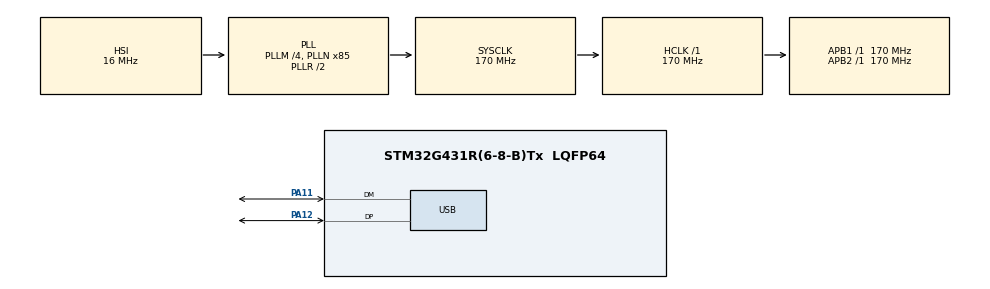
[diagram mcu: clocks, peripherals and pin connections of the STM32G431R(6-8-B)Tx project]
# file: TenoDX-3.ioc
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Mcu.Family=STM32G4
Mcu.Name=STM32G431R(6-8-B)Tx
Mcu.Package=LQFP64
NVIC.PriorityGroup=NVIC_PRIORITYGROUP_4
NVIC.USB_LP_IRQn=true\:0\:0\:false\:false\:true\:true\:true\:true
PA11.Mode=Device
PA11.Signal=USB_DM
PA12.Mode=Device
PA12.Signal=USB_DP
PA13.Mode=Serial_Wire
PA13.Signal=SYS_JTMS-SWDIO
PA14.Mode=Serial_Wire
PA14.Signal=SYS_JTCK-SWCLK
PF0-OSC_IN.Mode=HSE-External-Oscillator
PF0-OSC_IN.Signal=RCC_OSC_IN
PF1-OSC_OUT.Mode=HSE-External-Oscillator
PF1-OSC_OUT.Signal=RCC_OSC_OUT
ProjectManager.HeapSize=0x200
ProjectManager.StackSize=0x400
ProjectManager.TargetToolchain=STM32CubeIDE
RCC.ADC12Freq_Value=170000000
RCC.AHBFreq_Value=170000000
RCC.APB1Freq_Value=170000000
RCC.APB1TimFreq_Value=170000000
RCC.APB2Freq_Value=170000000
RCC.APB2TimFreq_Value=170000000
RCC.CK48CLockSelection=RCC_USBCLKSOURCE_HSI48
RCC.CortexFreq_Value=170000000
RCC.EXTERNAL_CLOCK_VALUE=12288000
RCC.HCLKFreq_Value=170000000
RCC.HSE_VALUE=8000000
RCC.HSI48_VALUE=48000000
RCC.HSI_VALUE=16000000
RCC.LSE_VALUE=32768
RCC.PLLM=RCC_PLLM_DIV4
RCC.PLLN=85
RCC.PLLQ=RCC_PLLQ_DIV4
RCC.SYSCLKFreq_VALUE=170000000
RCC.SYSCLKSource=RCC_SYSCLKSOURCE_PLLCLK
RCC.USBFreq_Value=48000000
RCC.VCOOutputFreq_Value=340000000
VP_SYS_VS_DBSignals.Mode=DisableDeadBatterySignals
board=custom

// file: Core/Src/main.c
/* USER CODE BEGIN Header */
/**
  ******************************************************************************
  * @file           : main.c
  * @brief          : Main program body
  ******************************************************************************
  * @attention
  *
  * Copyright (c) 2026 STMicroelectronics.
  * All rights reserved.
  *
  * This software is licensed under terms that can be found in the LICENSE file
  * in the root directory of this software component.
  * If no LICENSE file comes with this software, it is provided AS-IS.
  *
  ******************************************************************************
  */
/* USER CODE END Header */
#include "main.h"
#include "usb.h"
#include "gpio.h"

/* USER CODE BEGIN Includes */
#include "tusb.h" // 必须包含头文件
/* USER CODE END Includes */

void SystemClock_Config(void);

int main(void)
{

  /* MCU Configuration--------------------------------------------------------*/

  /* Reset of all peripherals, Initializes the Flash interface and the Systick. */
  HAL_Init();

  /* Configure the system clock */
  SystemClock_Config();

  /* Initialize all configured peripherals */
  MX_GPIO_Init();
  MX_USB_PCD_Init();
  /* USER CODE BEGIN 2 */
  PWR->CR2 |= PWR_CR2_USV;
  tusb_init();
  /* USER CODE END 2 */

  /* Infinite loop */
  /* USER CODE BEGIN WHILE */
  while (1)
  {
	  tud_task();
    /* USER CODE END WHILE */

  }
}

void SystemClock_Config(void)
{
  RCC_OscInitTypeDef RCC_OscInitStruct = {0};
  RCC_ClkInitTypeDef RCC_ClkInitStruct = {0};

  /** Configure the main internal regulator output voltage
  */
  HAL_PWREx_ControlVoltageScaling(PWR_REGULATOR_VOLTAGE_SCALE1_BOOST);

  /** Initializes the RCC Oscillators according to the specified parameters
  * in the RCC_OscInitTypeDef structure.
  */
  RCC_OscInitStruct.OscillatorType = RCC_OSCILLATORTYPE_HSI|RCC_OSCILLATORTYPE_HSI48;
  RCC_OscInitStruct.HSIState = RCC_HSI_ON;
  RCC_OscInitStruct.HSICalibrationValue = RCC_HSICALIBRATION_DEFAULT;
  RCC_OscInitStruct.HSI48State = RCC_HSI48_ON;
  RCC_OscInitStruct.PLL.PLLState = RCC_PLL_ON;
  RCC_OscInitStruct.PLL.PLLSource = RCC_PLLSOURCE_HSI;
  RCC_OscInitStruct.PLL.PLLM = RCC_PLLM_DIV4;
  RCC_OscInitStruct.PLL.PLLN = 85;
  RCC_OscInitStruct.PLL.PLLP = RCC_PLLP_DIV2;
  RCC_OscInitStruct.PLL.PLLQ = RCC_PLLQ_DIV4;
  RCC_OscInitStruct.PLL.PLLR = RCC_PLLR_DIV2;
  if (HAL_RCC_OscConfig(&RCC_OscInitStruct) != HAL_OK)
  {
    Error_Handler();
  }

  /** Initializes the CPU, AHB and APB buses clocks
  */
  RCC_ClkInitStruct.ClockType = RCC_CLOCKTYPE_HCLK|RCC_CLOCKTYPE_SYSCLK
                              |RCC_CLOCKTYPE_PCLK1|RCC_CLOCKTYPE_PCLK2;
  RCC_ClkInitStruct.SYSCLKSource = RCC_SYSCLKSOURCE_PLLCLK;
  RCC_ClkInitStruct.AHBCLKDivider = RCC_SYSCLK_DIV1;
  RCC_ClkInitStruct.APB1CLKDivider = RCC_HCLK_DIV1;
  RCC_ClkInitStruct.APB2CLKDivider = RCC_HCLK_DIV1;

  if (HAL_RCC_ClockConfig(&RCC_ClkInitStruct, FLASH_LATENCY_4) != HAL_OK)
  {
    Error_Handler();
  }
}

/* USER CODE BEGIN 4 */
// -------------------------------------------------------------------------
// TinyUSB HID 回调函数实现 (必须提供，否则链接报错)
// -------------------------------------------------------------------------

// 当主机请求获取 HID 报告时调用 (Get Report)
uint16_t tud_hid_get_report_cb(uint8_t instance, uint8_t report_id, hid_report_type_t report_type, uint8_t* buffer, uint16_t reqlen)
{
  // 如果没有特殊处理，直接返回 0
  (void) instance;
  (void) report_id;
  (void) report_type;
  (void) buffer;
  (void) reqlen;
  return 0;
}

// 当主机发送设置 HID 报告的请求时调用 (Set Report)
// 例如：主机控制键盘的 Caps Lock 灯亮起，或者控制手柄震动
void tud_hid_set_report_cb(uint8_t instance, uint8_t report_id, hid_report_type_t report_type, uint8_t const* buffer, uint16_t bufsize)
{
  // 目前我们不需要处理电脑发来的 HID 设置指令，保持为空即可
  (void) instance;
  (void) report_id;
  (void) report_type;
  (void) buffer;
  (void) bufsize;
}
/* USER CODE END 4 */

void Error_Handler(void)
{
  __disable_irq();
  while (1)
  {
  }
}
